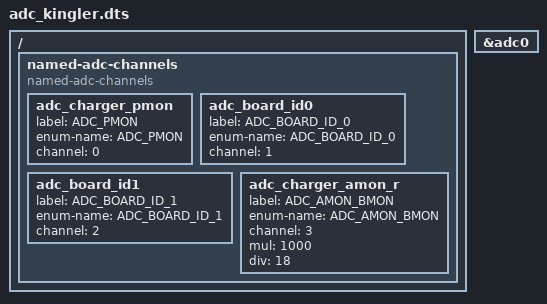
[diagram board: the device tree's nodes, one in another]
/* Copyright 2021 The Chromium OS Authors. All rights reserved.
 * Use of this source code is governed by a BSD-style license that can be
 * found in the LICENSE file.
 */

/ {
	 named-adc-channels {
		 compatible = "named-adc-channels";

		 adc_charger_pmon {
			 label = "ADC_PMON";
			 enum-name = "ADC_PMON";
			 channel = <0>;
		 };
		 adc_board_id0 {
			 label = "ADC_BOARD_ID_0";
			 enum-name = "ADC_BOARD_ID_0";
			 channel = <1>;
		 };
		 adc_board_id1 {
			 label = "ADC_BOARD_ID_1";
			 enum-name = "ADC_BOARD_ID_1";
			 channel = <2>;
		 };
		 adc_charger_amon_r {
			 label = "ADC_AMON_BMON";
			 enum-name = "ADC_AMON_BMON";
			 channel = <3>;
			 mul = <1000>;
			 div = <18>;
		 };
	 };
};

&adc0 {
	 status = "okay";
};
